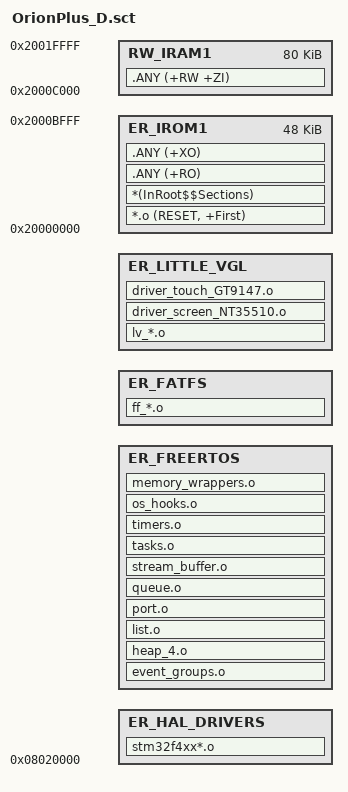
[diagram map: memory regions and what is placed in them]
; *************************************************************
; *** Custom Scatter-Loading Description File               ***
; *************************************************************

;
;   Currently there are various known code blocks in the firmware:
;
;   App_Core:   Global application control. Creation of main tasks, 
;               Settings management, Machine core control, etc.
;
;   App_HW:     Code to initialize and configure hardware peripherals.
;
;   App_UI:     User interface implementation.
;
;   App_GCode:  GCode parsing implementation. 
;
;   App_Motion: Movement planning and stepper motor control.
;
;   Drivers:    STM32F4 HAL drivers implementation (provided by ST). 
;               [Adr = 0x08001000, Sz = 0x4b10 = 19216 = 18.77 KB]
;
;   OS:         FreeRTOS source code, user hooks and new/delete wrappers. 0
;               [Adr = 0x08005b10, Sz = 0x2d8c = 11660 = 11.39 KB]
;
;   FileSystem: FreeRTOS+FAT source code.
;               [Adr = 0x0800889c, Sz = 0x0000 => Currently optimized out]
;
;   LittleVGL_Core:     Graphics library core.
;   LittleVGL_HAL:      Graphics library HAL.
;   LittleVGL_Misc:     Graphics library miscellaneous.
;   LittleVGL_Draw:     Graphics library drawing.
;   LittleVGL_Font:     Graphics library font handling.
;   LittleVGL_ObjX:     Graphics library widgets.
;   LittleVGL_Themes:   Graphics library themes.
;   LittleVGL_Drivers:  Graphics library TFT and touch drivers (custom)
;   
;   [Adr = 0x0800889c, Sz = 0x130b4 = 78004 = 76.18 KB]
;
;
;   Sums:  19216 + 11660 + 78004 = 108880 = 106.33 KB

LR_RAM1 0x20000000 0x00020000  {    ; load region (RAM) size_region
  ER_IROM1 0x20000000 0x0000C000  {  ; load address = execution address
   *.o (RESET, +First)
   *(InRoot$$Sections)
   .ANY (+RO)
   .ANY (+XO)
  }
  RW_IRAM1 0x2000C000 0x00014000  {  ; RW data
   .ANY (+RW +ZI)
  }
}

;   ER_IROM1 - Code into RAM [Vectors, user app, etc.]
;   Addr = 0x20000000,  Sz = 0x9114 = 37140 = 36.27 KB
;   Max Size = 0xC000 = 49152, Remains: 12012 bytes
;
;   RW_IRAM1 - Data into RAM 
;   Addr = 0x2000C000,  Sz = 0x13f78 = 81784 = 79.87 KB
;   Max Size = 0x14000 = 81920, Remains: 136 bytes

; Start from Sector 5 (Sectors of 128 KB)
LR_FLASH1 0x08020000 0x000E0000 {

  ER_HAL_DRIVERS +0 {
    stm32f4xx*.o
  }
  
  ER_FREERTOS +0 {
    event_groups.o
    heap_4.o
    list.o
    port.o
    queue.o
    stream_buffer.o
    tasks.o
    timers.o
    os_hooks.o
    memory_wrappers.o
  }
  
  ER_FATFS +0 {
    ff_*.o
  }
  
  ER_LITTLE_VGL +0 {
   lv_*.o
   driver_screen_NT35510.o
   driver_touch_GT9147.o
  }
  
}

